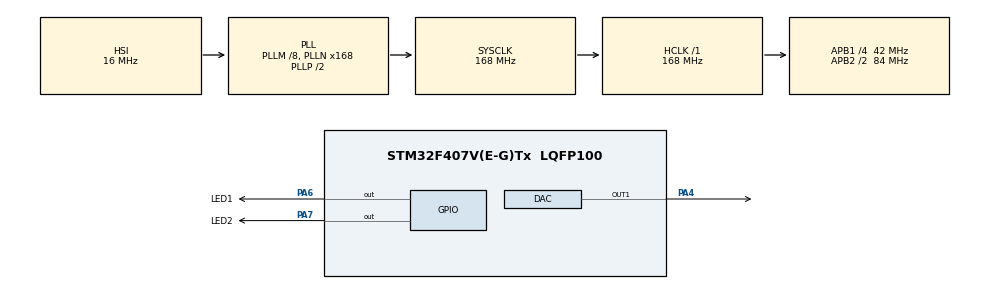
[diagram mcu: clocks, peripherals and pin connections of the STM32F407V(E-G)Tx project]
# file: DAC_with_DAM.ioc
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DAC.DAC_Trigger=DAC_TRIGGER_T6_TRGO
Dma.DAC1.0.Direction=DMA_MEMORY_TO_PERIPH
Dma.DAC1.0.FIFOMode=DMA_FIFOMODE_DISABLE
Dma.DAC1.0.Instance=DMA1_Stream5
Dma.DAC1.0.MemDataAlignment=DMA_MDATAALIGN_HALFWORD
Dma.DAC1.0.MemInc=DMA_MINC_ENABLE
Dma.DAC1.0.Mode=DMA_NORMAL
Dma.DAC1.0.PeriphDataAlignment=DMA_PDATAALIGN_HALFWORD
Dma.DAC1.0.PeriphInc=DMA_PINC_DISABLE
Dma.DAC1.0.Priority=DMA_PRIORITY_LOW
Dma.Request0=DAC1
Mcu.Family=STM32F4
Mcu.Name=STM32F407V(E-G)Tx
Mcu.Package=LQFP100
NVIC.DMA1_Stream5_IRQn=true\:0\:0\:false\:false\:true\:false
NVIC.PriorityGroup=NVIC_PRIORITYGROUP_4
NVIC.TIM6_DAC_IRQn=true\:0\:0\:false\:false\:true\:true
PA13.Mode=Serial_Wire
PA13.Signal=SYS_JTMS-SWDIO
PA14.Mode=Serial_Wire
PA14.Signal=SYS_JTCK-SWCLK
PA4.Signal=COMP_DAC1_group
PA6.GPIO_Label=LED1
PA6.Signal=GPIO_Output
PA7.GPIO_Label=LED2
PA7.Signal=GPIO_Output
PH0-OSC_IN.Mode=HSE-External-Oscillator
PH0-OSC_IN.Signal=RCC_OSC_IN
PH1-OSC_OUT.Mode=HSE-External-Oscillator
PH1-OSC_OUT.Signal=RCC_OSC_OUT
ProjectManager.HeapSize=0x200
ProjectManager.StackSize=0x400
ProjectManager.TargetToolchain=MDK-ARM V5
RCC.48MHZClocksFreq_Value=84000000
RCC.AHBFreq_Value=168000000
RCC.APB1CLKDivider=RCC_HCLK_DIV4
RCC.APB1Freq_Value=42000000
RCC.APB1TimFreq_Value=84000000
RCC.APB2CLKDivider=RCC_HCLK_DIV2
RCC.APB2Freq_Value=84000000
RCC.APB2TimFreq_Value=168000000
RCC.CortexFreq_Value=168000000
RCC.HCLKFreq_Value=168000000
RCC.HSE_VALUE=8000000
RCC.HSI_VALUE=16000000
RCC.LSE_VALUE=32768
RCC.PLLM=8
RCC.PLLN=168
RCC.SYSCLKFreq_VALUE=168000000
RCC.SYSCLKSource=RCC_SYSCLKSOURCE_PLLCLK
RCC.VCOOutputFreq_Value=336000000
SH.COMP_DAC1_group.0=DAC_OUT1,DAC_OUT1
TIM6.Period=32000
TIM6.Prescaler=0
TIM6.TIM_MasterOutputTrigger=TIM_TRGO_UPDATE
VP_TIM6_VS_ClockSourceINT.Mode=Enable_Timer
board=custom

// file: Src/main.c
/**
  ******************************************************************************
  * @file           : main.c
  * @brief          : Main program body
  ******************************************************************************
  ** This notice applies to any and all portions of this file
  * that are not between comment pairs USER CODE BEGIN and
  * USER CODE END. Other portions of this file, whether
  * inserted by the user or by software development tools
  * are owned by their respective copyright owners.
  *
  * COPYRIGHT(c) 2019 STMicroelectronics
  *
  * Redistribution and use in source and binary forms, with or without modification,
  * are permitted provided that the following conditions are met:
  *   1. Redistributions of source code must retain the above copyright notice,
  *      this list of conditions and the following disclaimer.
  *   2. Redistributions in binary form must reproduce the above copyright notice,
  *      this list of conditions and the following disclaimer in the documentation
  *      and/or other materials provided with the distribution.
  *   3. Neither the name of STMicroelectronics nor the names of its contributors
  *      may be used to endorse or promote products derived from this software
  *      without specific prior written permission.
  *
  * THIS SOFTWARE IS PROVIDED BY THE COPYRIGHT HOLDERS AND CONTRIBUTORS "AS IS"
  * AND ANY EXPRESS OR IMPLIED WARRANTIES, INCLUDING, BUT NOT LIMITED TO, THE
  * IMPLIED WARRANTIES OF MERCHANTABILITY AND FITNESS FOR A PARTICULAR PURPOSE ARE
  * DISCLAIMED. IN NO EVENT SHALL THE COPYRIGHT HOLDER OR CONTRIBUTORS BE LIABLE
  * FOR ANY DIRECT, INDIRECT, INCIDENTAL, SPECIAL, EXEMPLARY, OR CONSEQUENTIAL
  * DAMAGES (INCLUDING, BUT NOT LIMITED TO, PROCUREMENT OF SUBSTITUTE GOODS OR
  * SERVICES; LOSS OF USE, DATA, OR PROFITS; OR BUSINESS INTERRUPTION) HOWEVER
  * CAUSED AND ON ANY THEORY OF LIABILITY, WHETHER IN CONTRACT, STRICT LIABILITY,
  * OR TORT (INCLUDING NEGLIGENCE OR OTHERWISE) ARISING IN ANY WAY OUT OF THE USE
  * OF THIS SOFTWARE, EVEN IF ADVISED OF THE POSSIBILITY OF SUCH DAMAGE.
  *
  ******************************************************************************
  */
#include "main.h"
#include "stm32f4xx_hal.h"

DAC_HandleTypeDef hdac;
DMA_HandleTypeDef hdma_dac1;

TIM_HandleTypeDef htim6;

/* USER CODE BEGIN PV */
/* Private variables ---------------------------------------------------------*/

uint16_t sine_wave_array[32] = {2047, 1648, 1264, 910, 600,  345,
                    156, 39,  0,  39,  156,  345,
                    600, 910, 1264, 1648, 2048, 2447,
                    2831, 3185, 3495, 3750, 3939, 4056,
                    4095, 4056, 3939, 3750, 3495, 3185,
                    2831, 2447};
uint16_t my_array[32] = {0,0,0,0,4095,4095,4095,4095,0,0,0,0,4095,4095,4095,4095,
												 0,0,0,0,4095,4095,4095,4095,0,0,0,0,4095,4095,4095,4095};
uint16_t count = 0;
/* USER CODE END PV */

void SystemClock_Config(void);
static void MX_GPIO_Init(void);
static void MX_DMA_Init(void);
static void MX_DAC_Init(void);
static void MX_TIM6_Init(void);

/* USER CODE BEGIN PFP */
/* Private function prototypes -----------------------------------------------*/
void HAL_DAC_ConvCpltCallbackCh1(DAC_HandleTypeDef* hdac);
/* USER CODE END PFP */

int main(void)
{

  /* MCU Configuration----------------------------------------------------------*/

  /* Reset of all peripherals, Initializes the Flash interface and the Systick. */
  HAL_Init();

  /* Configure the system clock */
  SystemClock_Config();

  /* Initialize all configured peripherals */
  MX_GPIO_Init();
  MX_DMA_Init();
  MX_DAC_Init();
  MX_TIM6_Init();
  /* USER CODE BEGIN 2 */

	HAL_TIM_Base_Start(&htim6);
	HAL_DAC_Start(&hdac,DAC_CHANNEL_1);
	HAL_DAC_Start_DMA(&hdac, DAC_CHANNEL_1, (uint32_t*)sine_wave_array, 32, DAC_ALIGN_12B_R);
  /* USER CODE END 2 */

  /* Infinite loop */
  while (1)
  {

  /* USER CODE BEGIN 3 */
		HAL_GPIO_WritePin(GPIOA,LED2_Pin,1);
		HAL_GPIO_WritePin(GPIOA,LED1_Pin,0);
		HAL_Delay(200);
		HAL_GPIO_WritePin(GPIOA,LED2_Pin,0);
		HAL_GPIO_WritePin(GPIOA,LED1_Pin,1);
		HAL_Delay(200);

	}
  /* USER CODE END 3 */

}

void SystemClock_Config(void)
{

  RCC_OscInitTypeDef RCC_OscInitStruct;
  RCC_ClkInitTypeDef RCC_ClkInitStruct;

    /**Configure the main internal regulator output voltage
    */
  __HAL_RCC_PWR_CLK_ENABLE();

  __HAL_PWR_VOLTAGESCALING_CONFIG(PWR_REGULATOR_VOLTAGE_SCALE1);

    /**Initializes the CPU, AHB and APB busses clocks
    */
  RCC_OscInitStruct.OscillatorType = RCC_OSCILLATORTYPE_HSI;
  RCC_OscInitStruct.HSIState = RCC_HSI_ON;
  RCC_OscInitStruct.HSICalibrationValue = 16;
  RCC_OscInitStruct.PLL.PLLState = RCC_PLL_ON;
  RCC_OscInitStruct.PLL.PLLSource = RCC_PLLSOURCE_HSI;
  RCC_OscInitStruct.PLL.PLLM = 8;
  RCC_OscInitStruct.PLL.PLLN = 168;
  RCC_OscInitStruct.PLL.PLLP = RCC_PLLP_DIV2;
  RCC_OscInitStruct.PLL.PLLQ = 4;
  if (HAL_RCC_OscConfig(&RCC_OscInitStruct) != HAL_OK)
  {
    _Error_Handler(__FILE__, __LINE__);
  }

    /**Initializes the CPU, AHB and APB busses clocks
    */
  RCC_ClkInitStruct.ClockType = RCC_CLOCKTYPE_HCLK|RCC_CLOCKTYPE_SYSCLK
                              |RCC_CLOCKTYPE_PCLK1|RCC_CLOCKTYPE_PCLK2;
  RCC_ClkInitStruct.SYSCLKSource = RCC_SYSCLKSOURCE_PLLCLK;
  RCC_ClkInitStruct.AHBCLKDivider = RCC_SYSCLK_DIV1;
  RCC_ClkInitStruct.APB1CLKDivider = RCC_HCLK_DIV4;
  RCC_ClkInitStruct.APB2CLKDivider = RCC_HCLK_DIV2;

  if (HAL_RCC_ClockConfig(&RCC_ClkInitStruct, FLASH_LATENCY_5) != HAL_OK)
  {
    _Error_Handler(__FILE__, __LINE__);
  }

    /**Configure the Systick interrupt time
    */
  HAL_SYSTICK_Config(HAL_RCC_GetHCLKFreq()/1000);

    /**Configure the Systick
    */
  HAL_SYSTICK_CLKSourceConfig(SYSTICK_CLKSOURCE_HCLK);

  /* SysTick_IRQn interrupt configuration */
  HAL_NVIC_SetPriority(SysTick_IRQn, 0, 0);
}

/* DAC init function */
static void MX_DAC_Init(void)
{

  DAC_ChannelConfTypeDef sConfig;

    /**DAC Initialization
    */
  hdac.Instance = DAC;
  if (HAL_DAC_Init(&hdac) != HAL_OK)
  {
    _Error_Handler(__FILE__, __LINE__);
  }

    /**DAC channel OUT1 config
    */
  sConfig.DAC_Trigger = DAC_TRIGGER_T6_TRGO;
  sConfig.DAC_OutputBuffer = DAC_OUTPUTBUFFER_ENABLE;
  if (HAL_DAC_ConfigChannel(&hdac, &sConfig, DAC_CHANNEL_1) != HAL_OK)
  {
    _Error_Handler(__FILE__, __LINE__);
  }

}

/* TIM6 init function */
static void MX_TIM6_Init(void)
{

  TIM_MasterConfigTypeDef sMasterConfig;

  htim6.Instance = TIM6;
  htim6.Init.Prescaler = 1000;
  htim6.Init.CounterMode = TIM_COUNTERMODE_UP;
  htim6.Init.Period = 32000;
  if (HAL_TIM_Base_Init(&htim6) != HAL_OK)
  {
    _Error_Handler(__FILE__, __LINE__);
  }

  sMasterConfig.MasterOutputTrigger = TIM_TRGO_UPDATE;
  sMasterConfig.MasterSlaveMode = TIM_MASTERSLAVEMODE_DISABLE;
  if (HAL_TIMEx_MasterConfigSynchronization(&htim6, &sMasterConfig) != HAL_OK)
  {
    _Error_Handler(__FILE__, __LINE__);
  }

}

static void MX_DMA_Init(void)
{
  /* DMA controller clock enable */
  __HAL_RCC_DMA1_CLK_ENABLE();

  /* DMA interrupt init */
  /* DMA1_Stream5_IRQn interrupt configuration */
  HAL_NVIC_SetPriority(DMA1_Stream5_IRQn, 0, 0);
  HAL_NVIC_EnableIRQ(DMA1_Stream5_IRQn);

}

/** Configure pins as
        * Analog
        * Input
        * Output
        * EVENT_OUT
        * EXTI
*/
static void MX_GPIO_Init(void)
{

  GPIO_InitTypeDef GPIO_InitStruct;

  /* GPIO Ports Clock Enable */
  __HAL_RCC_GPIOH_CLK_ENABLE();
  __HAL_RCC_GPIOA_CLK_ENABLE();

  /*Configure GPIO pin Output Level */
  HAL_GPIO_WritePin(GPIOA, LED1_Pin|LED2_Pin, GPIO_PIN_RESET);

  /*Configure GPIO pins : LED1_Pin LED2_Pin */
  GPIO_InitStruct.Pin = LED1_Pin|LED2_Pin;
  GPIO_InitStruct.Mode = GPIO_MODE_OUTPUT_PP;
  GPIO_InitStruct.Pull = GPIO_NOPULL;
  GPIO_InitStruct.Speed = GPIO_SPEED_FREQ_LOW;
  HAL_GPIO_Init(GPIOA, &GPIO_InitStruct);

}

/* USER CODE BEGIN 4 */

void HAL_DAC_ConvCpltCallbackCh1(DAC_HandleTypeDef* hdac)
{
	HAL_DAC_Stop_DMA(hdac, DAC_CHANNEL_1);
	if(++count%2)
		HAL_DAC_Start_DMA(hdac, DAC_CHANNEL_1, (uint32_t*)my_array, 32, DAC_ALIGN_12B_R);
		//memcpy(data_array,&my_array[0],64);
	else
		HAL_DAC_Start_DMA(hdac, DAC_CHANNEL_1, (uint32_t*)sine_wave_array, 32, DAC_ALIGN_12B_R);
		//memcpy(data_array,&sine_wave_array[0],64);
}

/* USER CODE END 4 */

void _Error_Handler(char *file, int line)
{
  while(1)
  {
  }
}

/************************ (C) COPYRIGHT STMicroelectronics *****END OF FILE****/
